# PCIE0_CORE_DBN_CFG_PCIE_CORE register map
Vendor: Texas Instruments
Peripheral module from a debugger description file (folder J7_AHP).
Registers are 32-bit, read-write, reset 0x0 unless marked. A register's access mark holds for its fields unless they carry their own. Offsets are as the file gives them; lines under a group give offsets from that group; [hi:lo] are bit positions; {n}, {i} and the like mark numbered series; 'fields as' and 'values as' point back to an identical list; <NAME> marks a mode.

## PCIE0_CORE_DBN_CFG_PCIE_CORE (part 1 of 6)
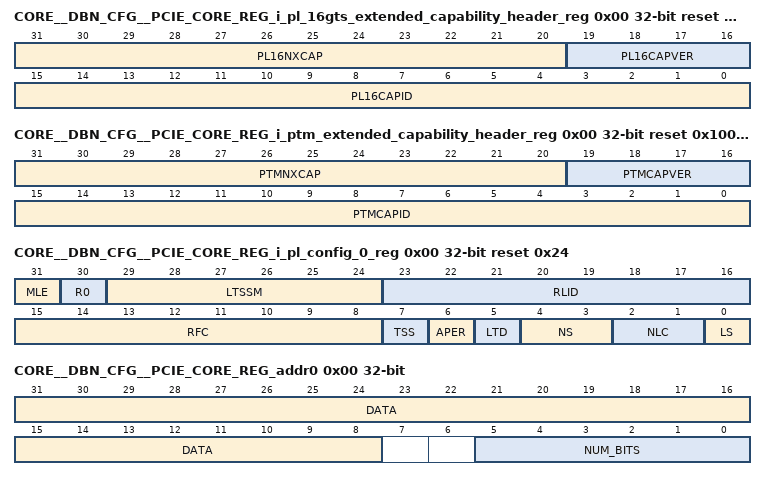
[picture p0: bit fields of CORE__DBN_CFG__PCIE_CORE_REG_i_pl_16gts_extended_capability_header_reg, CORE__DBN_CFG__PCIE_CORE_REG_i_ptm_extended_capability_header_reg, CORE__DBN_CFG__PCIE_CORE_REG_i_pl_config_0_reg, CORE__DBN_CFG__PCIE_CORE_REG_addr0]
0x00 CORE__DBN_CFG__PCIE_CORE_REG_i_pl_16gts_extended_capability_header_reg ro reset 0xA2010026
  [31:20] PL16NXCAP — The offset to the next PCI Extended Capability structure.
  [19:16] PL16CAPVER — This field is a PCI-SIG defined version number that indicates the version of the Capability structure present.
  [15:0] PL16CAPID — Indicates that the associated extended capability structure is for Physical layer 16 GT/s. This field returns a Capability ID of 0026h.
0x00 CORE__DBN_CFG__PCIE_CORE_REG_i_ptm_extended_capability_header_reg ro reset 0x1001F
  [31:20] PTMNXCAP — The offset to the next PCIe Extended Capability structure.
  [19:16] PTMCAPVER — This field is a PCI-SIG defined version number that indicates the version of the Capability structure present.
  [15:0] PTMCAPID — Indicates that the associated extended capability structure is for Precision Time Measurement capability. This field returns a Capability ID of 001Fh.
0x00 CORE__DBN_CFG__PCIE_CORE_REG_i_pl_config_0_reg access per field reset 0x24
  [31] MLE rw — When the Controller is operating as a Root Port, setting this to 1 causes the LTSSM to initiate a loopback and become the loopback master. This bit is not used in the EndPoint Mode.
  [30] R0 ro — A 1 in this field indicates that the remote node advertised Linkwidth Upconfigure Capability in the training sequences in the Configuration.Complete state when the link came up. A 0 indicates that the remote node did not set the Link Upconfigure bit.
  [29:24] LTSSM ro — Current state of the LTSSM. The encoding of the states is given in Appendix C.
  [23:16] RLID ro — Link ID received from other side during link training.
  [15:8] RFC ro — FTS count received from the other side during link training for use at the 2.5 GT/s link speed. The Controller transmits this many FTS sequences while exiting the L0S state, when operating at the 2.5 GT/s speed.
  [7] TSS rw — This bit drives the PIPE_TX_SWING output of the Controller.
  [6] APER rw — This bit controls the reporting of Errors Detected by the PHY. The Errors Detected by the PHY include:- - Received errors indicated on PIPE RxStatus interface, - 8.0 GT/s Invalid Sync Header received error, - 16.0 GT/s Invalid Sync Header received error, If PHY Error Reporting bit is set to 0, the Controller will only report those errors that caused a TLP or DLLP to be dropped because of a Detected PHY Error. If PHY Error Reporting bit is set to 1, the Controller will report all Detected PHY Errors regardless of whether a TLP or DLLP was dropped. The following registers report PHY error in conjunction with this bit: - Correctable Error Status Register, i_corr_err_status, bit-0, Receiver Error Status - Local Error and Status Register, i_local_error_status_register, bit-7, Phy Error In addition to the Errors Detected by the PHY[PCS], the Controller detects the following Physical Layer Protocol Framing Errors: - Framing Errors in the received DLLP and TLP - Ordered Set Block Received Without EDS - Data Block Received After EDS - Illegal Ordered Set Block Received After EDS - Ordered Set Block Received After Skip OS Note: These Errors are always reported independent of the setting of this bit.
  [5] LTD ro — The state of this bit indicates whether the Controller completed link training as an upstream port[EndPoint][=0] or a downstream port[Root Port][=1]. Default value depends on CORE_TYPE strap pin.
  [4:3] NS ro — Current operating speed of link [00 = 2.5G, 01 = 5G, 10 = 8G, 11 = 16G].
  [2:1] NLC ro — Lane count negotiated with other side during link training [00 = x1, 01 = x2, 10 = x4, 11 = x8].
  [0] LS ro — Current state of link [1 = link training complete, 0 = link training not complete].
0x00 CORE__DBN_CFG__PCIE_CORE_REG_addr0 access per field
  [31:8] DATA rw — Bits [31:8] of PCIe Address Register for region N
  [5:0] NUM_BITS rw — Number_bits + 1 bits are passed through from AXI address to the PCIe address
0x00 CORE__DBN_CFG__PCIE_CORE_REG_addr0 access per field
  fields as CORE__DBN_CFG__PCIE_CORE_REG_addr0
0x00 CORE__DBN_CFG__PCIE_CORE_REG_addr0 access per field
  fields as CORE__DBN_CFG__PCIE_CORE_REG_addr0
0x00 CORE__DBN_CFG__PCIE_CORE_REG_addr0 access per field
  fields as CORE__DBN_CFG__PCIE_CORE_REG_addr0
0x00 CORE__DBN_CFG__PCIE_CORE_REG_addr0 access per field
  fields as CORE__DBN_CFG__PCIE_CORE_REG_addr0
0x00 CORE__DBN_CFG__PCIE_CORE_REG_addr0 access per field
  fields as CORE__DBN_CFG__PCIE_CORE_REG_addr0
0x00 CORE__DBN_CFG__PCIE_CORE_REG_addr0 access per field
  fields as CORE__DBN_CFG__PCIE_CORE_REG_addr0
0x00 CORE__DBN_CFG__PCIE_CORE_REG_addr0 access per field
  fields as CORE__DBN_CFG__PCIE_CORE_REG_addr0
0x00 CORE__DBN_CFG__PCIE_CORE_REG_addr0 access per field
  fields as CORE__DBN_CFG__PCIE_CORE_REG_addr0
0x00 CORE__DBN_CFG__PCIE_CORE_REG_addr0 access per field
  fields as CORE__DBN_CFG__PCIE_CORE_REG_addr0
0x00 CORE__DBN_CFG__PCIE_CORE_REG_addr0 access per field
  fields as CORE__DBN_CFG__PCIE_CORE_REG_addr0
0x00 CORE__DBN_CFG__PCIE_CORE_REG_addr0 access per field
  fields as CORE__DBN_CFG__PCIE_CORE_REG_addr0
0x00 CORE__DBN_CFG__PCIE_CORE_REG_addr0 access per field
  fields as CORE__DBN_CFG__PCIE_CORE_REG_addr0
0x00 CORE__DBN_CFG__PCIE_CORE_REG_addr0 access per field
  fields as CORE__DBN_CFG__PCIE_CORE_REG_addr0
0x00 CORE__DBN_CFG__PCIE_CORE_REG_addr0 access per field
  fields as CORE__DBN_CFG__PCIE_CORE_REG_addr0
0x00 CORE__DBN_CFG__PCIE_CORE_REG_addr0 access per field
  fields as CORE__DBN_CFG__PCIE_CORE_REG_addr0
0x00 CORE__DBN_CFG__PCIE_CORE_REG_addr0 access per field
  fields as CORE__DBN_CFG__PCIE_CORE_REG_addr0
0x00 CORE__DBN_CFG__PCIE_CORE_REG_addr0 access per field
  fields as CORE__DBN_CFG__PCIE_CORE_REG_addr0
0x00 CORE__DBN_CFG__PCIE_CORE_REG_addr0 access per field
  fields as CORE__DBN_CFG__PCIE_CORE_REG_addr0
0x00 CORE__DBN_CFG__PCIE_CORE_REG_addr0 access per field
  fields as CORE__DBN_CFG__PCIE_CORE_REG_addr0
0x00 CORE__DBN_CFG__PCIE_CORE_REG_addr0 access per field
  fields as CORE__DBN_CFG__PCIE_CORE_REG_addr0
0x00 CORE__DBN_CFG__PCIE_CORE_REG_addr0 access per field
  fields as CORE__DBN_CFG__PCIE_CORE_REG_addr0
0x00 CORE__DBN_CFG__PCIE_CORE_REG_addr0 access per field
  fields as CORE__DBN_CFG__PCIE_CORE_REG_addr0
0x00 CORE__DBN_CFG__PCIE_CORE_REG_addr0 access per field
  fields as CORE__DBN_CFG__PCIE_CORE_REG_addr0
0x00 CORE__DBN_CFG__PCIE_CORE_REG_addr0 access per field
  fields as CORE__DBN_CFG__PCIE_CORE_REG_addr0
0x00 CORE__DBN_CFG__PCIE_CORE_REG_addr0 access per field
  fields as CORE__DBN_CFG__PCIE_CORE_REG_addr0
0x00 CORE__DBN_CFG__PCIE_CORE_REG_addr0 access per field
  fields as CORE__DBN_CFG__PCIE_CORE_REG_addr0
0x00 CORE__DBN_CFG__PCIE_CORE_REG_addr0 access per field
  fields as CORE__DBN_CFG__PCIE_CORE_REG_addr0
0x00 CORE__DBN_CFG__PCIE_CORE_REG_addr0 access per field
  fields as CORE__DBN_CFG__PCIE_CORE_REG_addr0
0x00 CORE__DBN_CFG__PCIE_CORE_REG_addr0 access per field
  fields as CORE__DBN_CFG__PCIE_CORE_REG_addr0
0x00 CORE__DBN_CFG__PCIE_CORE_REG_addr0 access per field
  fields as CORE__DBN_CFG__PCIE_CORE_REG_addr0
0x00 CORE__DBN_CFG__PCIE_CORE_REG_addr0 access per field
  fields as CORE__DBN_CFG__PCIE_CORE_REG_addr0
0x00 CORE__DBN_CFG__PCIE_CORE_REG_addr0 access per field
  [31:8] DATA rw — Bits [31:8] of AXI Address Register for BAR N
  [5:0] NUM_BITS rw — The value programmed in this register +1 bits are passed through from PCIe to AXI
0x00 CORE__DBN_CFG__PCIE_CORE_REG_addr0 access per field
  [31:8] DATA rw — Bits [31:8] of AXI Address Register for BAR N
  [5:0] NUM_BITS rw — The value programmed in this register +1 bits are passed through from PCIe to AXI
0x00 CORE__DBN_CFG__PCIE_CORE_REG_addr0 access per field
  [31:8] DATA rw — Bits [31:8] of AXI Address Register for BAR N
  [5:0] NUM_BITS rw — The value programmed in this register +1 bits are passed through from PCIe to AXI
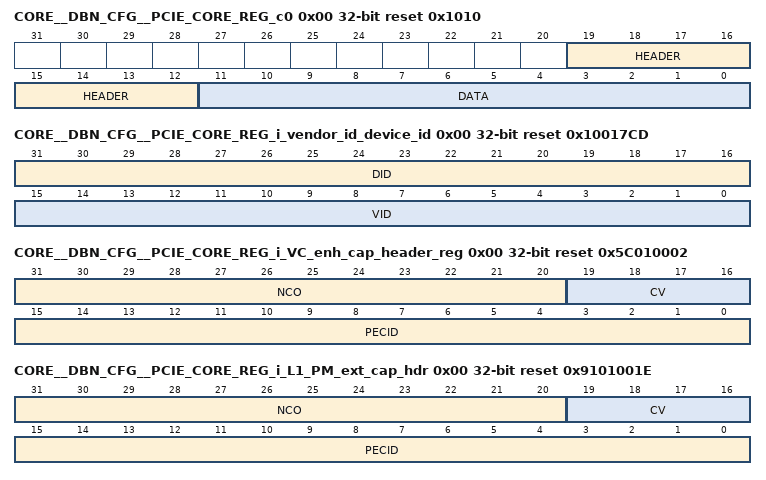
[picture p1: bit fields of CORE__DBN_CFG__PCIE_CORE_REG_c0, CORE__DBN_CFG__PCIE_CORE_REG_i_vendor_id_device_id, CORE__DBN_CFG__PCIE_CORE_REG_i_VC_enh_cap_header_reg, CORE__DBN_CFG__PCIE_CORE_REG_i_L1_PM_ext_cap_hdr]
0x00 CORE__DBN_CFG__PCIE_CORE_REG_c0 reset 0x1010
  [19:12] HEADER — This is the threshold value of the header credits required which is used to flag credit availability in AXI wrapper
  [11:0] DATA — This is the threshold value of the payload credits required which is used to flag credit availability in AXI wrapper
0x00 CORE__DBN_CFG__PCIE_CORE_REG_L0
  [0] CLEAR_LINK_DOWN_BIT_TO_PROCEED — This bit will be set when link down reset comes. client should clear this bit before issueing new traffic to the core
0x00 CORE__DBN_CFG__PCIE_CORE_REG_i_vendor_id_device_id ro reset 0x10017CD
  [31:16] DID — Device ID assigned by the manufacturer of the device. On power-up, the Controller sets it to the value defined in the RTL file reg_defaults.h. This field can be written from the APB bus by setting [21] bit high of the pcie_mgmt_APB_ADDR during a local management register write.
  [15:0] VID — This is the Vendor ID assigned by PCI SIG to the manufacturer of the device. The Vendor ID is set in the Vendor ID Register within the local management register block.
0x00 CORE__DBN_CFG__PCIE_CORE_REG_i_VC_enh_cap_header_reg ro reset 0x5C010002
  [31:20] NCO — Indicates offset to the next PCI Express capability structure. The default next pointer value is dynamic and is dependent on whether the strap or LMI bits are set.
  [19:16] CV — Specifies the SIG assigned value for the version of the capability structure. This field is set by default to 1, but can be modified independently for each PF from the local management bus.
  [15:0] PECID — This field is hardwired to the Capability ID assigned by PCI SIG to the VC Capability.
0x00 CORE__DBN_CFG__PCIE_CORE_REG_i_L1_PM_ext_cap_hdr ro reset 0x9101001E
  [31:20] NCO — Indicates offset to the next PCI Express capability structure. The default next pointer value is dynamic and is dependent on whether the strap or LMI bits are set.
  [19:16] CV — Specifies the SIG assigned value for the version of the capability structure. This field is set by default to 1, but can be modified from the local management bus.
  [15:0] PECID — This field is hardwired to the Capability ID assigned by PCI SIG to the L1 PM Substates Extended Capability Structure [001E hex].
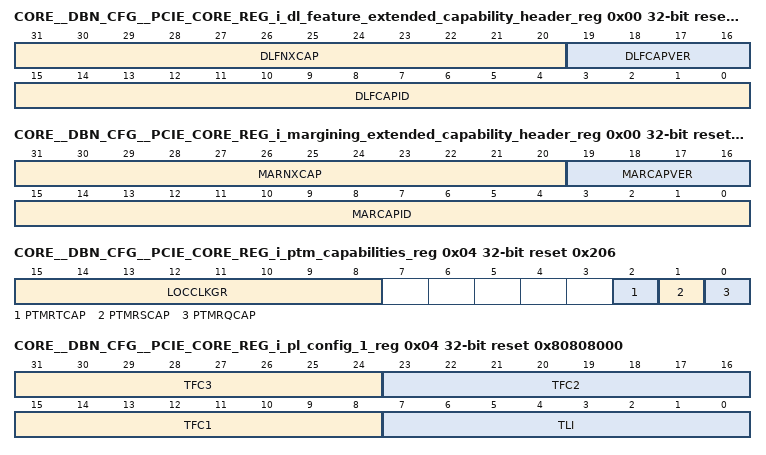
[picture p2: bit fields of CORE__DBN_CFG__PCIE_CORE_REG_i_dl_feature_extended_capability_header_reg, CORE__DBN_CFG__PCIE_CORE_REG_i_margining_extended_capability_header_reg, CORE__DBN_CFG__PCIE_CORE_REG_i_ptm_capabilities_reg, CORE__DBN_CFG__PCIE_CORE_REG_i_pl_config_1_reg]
0x00 CORE__DBN_CFG__PCIE_CORE_REG_i_dl_feature_extended_capability_header_reg ro reset 0x92010025
  [31:20] DLFNXCAP — The offset to the next PCI Extended Capability structure.
  [19:16] DLFCAPVER — This field is a PCI-SIG defined version number that indicates the version of the Capability structure present.
  [15:0] DLFCAPID — Indicates that the associated extended capability structure is the DL Feature Extended Capability. This field returns a Capability ID of 0025h.
0x00 CORE__DBN_CFG__PCIE_CORE_REG_i_margining_extended_capability_header_reg ro reset 0x9C010027
  [31:20] MARNXCAP — The offset to the next PCI Extended Capability structure.
  [19:16] MARCAPVER — This field is a PCI-SIG defined version number that indicates the version of the Capability structure present.
  [15:0] MARCAPID — Indicates that the associated extended capability structure is the Margining Extended Capability. This field returns a Capability ID of 0027h.
0x04 CORE__DBN_CFG__PCIE_CORE_REG_i_pl_16gts_capabilities_reg access not given reset not defined
0x04 CORE__DBN_CFG__PCIE_CORE_REG_i_ptm_capabilities_reg ro reset 0x206
  [15:8] LOCCLKGR — In RC Mode: The Controller uses the CORE_CLK as the Local Clock for PTM. This field is used to indicate the Time Period of the CORE_CLK. If the PTM Root Select is 1, then CORE_CLK is used to provide PTM Master Time. If the PTM Root Select is 0, then CORE_CLK is used to locally track the PTM Master Time received on the PTM_LOCAL_TIMER_IN[63:0] input. By default, this field is set to 8'd2. This bit can be programmed through the local management APB interface if required.
  [2] PTMRTCAP — This bit is used to indicate that the Controller implements PTM Time Source Role and is capable of serving as PTM Root. By default, this bit is set to 1 when the Controller is in RC Mode. This bit can be programmed through the local management APB interface if required. Note: If this bit is programmed to 1, then the PTM Responder Capable bit must also be programmed to 1 by FW.
  [1] PTMRSCAP — This bit is used to indicate support for PTM Responder Role. By default, this bit is set to 1 when the Controller is in RC Mode. This bit can be programmed through the local management APB interface if required. Note: If the PTM Root Capable is programmed to 1, then this bit must also be programmed to 1 by FW.
  [0] PTMRQCAP — This bit is used to indicate support for PTM Requester Role. By default, this bit is set to 0 when the Controller is in RC Mode. This bit can be programmed through the local management APB interface if required.
0x04 CORE__DBN_CFG__PCIE_CORE_REG_i_pl_config_1_reg reset 0x80808000
  [31:24] TFC3 — FTS count transmitted by the Controller in TS1/TS2 sequences during link training. This value must be set based on the time needed by the receiver to acquire sync while exiting from L0S state.
  [23:16] TFC2 — FTS count transmitted by the Controller in TS1/TS2 sequences during link training. This value must be set based on the time needed by the receiver to acquire sync while exiting from L0S state.
  [15:8] TFC1 — FTS count transmitted by the Controller in TS1/TS2 sequences during link training. This value must be set based on the time needed by the receiver to acquire sync while exiting from L0S state.
  [7:0] TLI — Link ID transmitted by the device in training sequences in the Root Port mode.
0x04 CORE__DBN_CFG__PCIE_CORE_REG_addr1
  [31:0] DATA — Bits [63:32] of PCIe Address Register for region N
0x04 CORE__DBN_CFG__PCIE_CORE_REG_addr1
  [31:0] DATA — Bits [63:32] of PCIe Address Register for region N
0x04 CORE__DBN_CFG__PCIE_CORE_REG_addr1
  [31:0] DATA — Bits [63:32] of PCIe Address Register for region N
0x04 CORE__DBN_CFG__PCIE_CORE_REG_addr1
  [31:0] DATA — Bits [63:32] of PCIe Address Register for region N
0x04 CORE__DBN_CFG__PCIE_CORE_REG_addr1
  [31:0] DATA — Bits [63:32] of PCIe Address Register for region N
0x04 CORE__DBN_CFG__PCIE_CORE_REG_addr1
  [31:0] DATA — Bits [63:32] of PCIe Address Register for region N
0x04 CORE__DBN_CFG__PCIE_CORE_REG_addr1
  [31:0] DATA — Bits [63:32] of PCIe Address Register for region N
0x04 CORE__DBN_CFG__PCIE_CORE_REG_addr1
  [31:0] DATA — Bits [63:32] of PCIe Address Register for region N
0x04 CORE__DBN_CFG__PCIE_CORE_REG_addr1
  [31:0] DATA — Bits [63:32] of PCIe Address Register for region N
0x04 CORE__DBN_CFG__PCIE_CORE_REG_addr1
  [31:0] DATA — Bits [63:32] of PCIe Address Register for region N
0x04 CORE__DBN_CFG__PCIE_CORE_REG_addr1
  [31:0] DATA — Bits [63:32] of PCIe Address Register for region N
0x04 CORE__DBN_CFG__PCIE_CORE_REG_addr1
  [31:0] DATA — Bits [63:32] of PCIe Address Register for region N
0x04 CORE__DBN_CFG__PCIE_CORE_REG_addr1
  [31:0] DATA — Bits [63:32] of PCIe Address Register for region N
0x04 CORE__DBN_CFG__PCIE_CORE_REG_addr1
  [31:0] DATA — Bits [63:32] of PCIe Address Register for region N
0x04 CORE__DBN_CFG__PCIE_CORE_REG_addr1
  [31:0] DATA — Bits [63:32] of PCIe Address Register for region N
0x04 CORE__DBN_CFG__PCIE_CORE_REG_addr1
  [31:0] DATA — Bits [63:32] of PCIe Address Register for region N
0x04 CORE__DBN_CFG__PCIE_CORE_REG_addr1
  [31:0] DATA — Bits [63:32] of PCIe Address Register for region N
0x04 CORE__DBN_CFG__PCIE_CORE_REG_addr1
  [31:0] DATA — Bits [63:32] of PCIe Address Register for region N
0x04 CORE__DBN_CFG__PCIE_CORE_REG_addr1
  [31:0] DATA — Bits [63:32] of PCIe Address Register for region N
0x04 CORE__DBN_CFG__PCIE_CORE_REG_addr1
  [31:0] DATA — Bits [63:32] of PCIe Address Register for region N
0x04 CORE__DBN_CFG__PCIE_CORE_REG_addr1
  [31:0] DATA — Bits [63:32] of PCIe Address Register for region N
0x04 CORE__DBN_CFG__PCIE_CORE_REG_addr1
  [31:0] DATA — Bits [63:32] of PCIe Address Register for region N
0x04 CORE__DBN_CFG__PCIE_CORE_REG_addr1
  [31:0] DATA — Bits [63:32] of PCIe Address Register for region N
0x04 CORE__DBN_CFG__PCIE_CORE_REG_addr1
  [31:0] DATA — Bits [63:32] of PCIe Address Register for region N
0x04 CORE__DBN_CFG__PCIE_CORE_REG_addr1
  [31:0] DATA — Bits [63:32] of PCIe Address Register for region N
0x04 CORE__DBN_CFG__PCIE_CORE_REG_addr1
  [31:0] DATA — Bits [63:32] of PCIe Address Register for region N
0x04 CORE__DBN_CFG__PCIE_CORE_REG_addr1
  [31:0] DATA — Bits [63:32] of PCIe Address Register for region N
0x04 CORE__DBN_CFG__PCIE_CORE_REG_addr1
  [31:0] DATA — Bits [63:32] of PCIe Address Register for region N
0x04 CORE__DBN_CFG__PCIE_CORE_REG_addr1
  [31:0] DATA — Bits [63:32] of PCIe Address Register for region N
0x04 CORE__DBN_CFG__PCIE_CORE_REG_addr1
  [31:0] DATA — Bits [63:32] of PCIe Address Register for region N
0x04 CORE__DBN_CFG__PCIE_CORE_REG_addr1
  [31:0] DATA — Bits [63:32] of PCIe Address Register for region N
0x04 CORE__DBN_CFG__PCIE_CORE_REG_addr1
  [31:0] DATA — Bits [63:32] of PCIe Address Register for region N
0x04 CORE__DBN_CFG__PCIE_CORE_REG_addr1
  [31:0] DATA — Bits [63:32] of AXI Address Register for BAR N
0x04 CORE__DBN_CFG__PCIE_CORE_REG_addr1
  [31:0] DATA — Bits [63:32] of AXI Address Register for BAR N
0x04 CORE__DBN_CFG__PCIE_CORE_REG_addr1
  [31:0] DATA — Bits [63:32] of AXI Address Register for BAR N
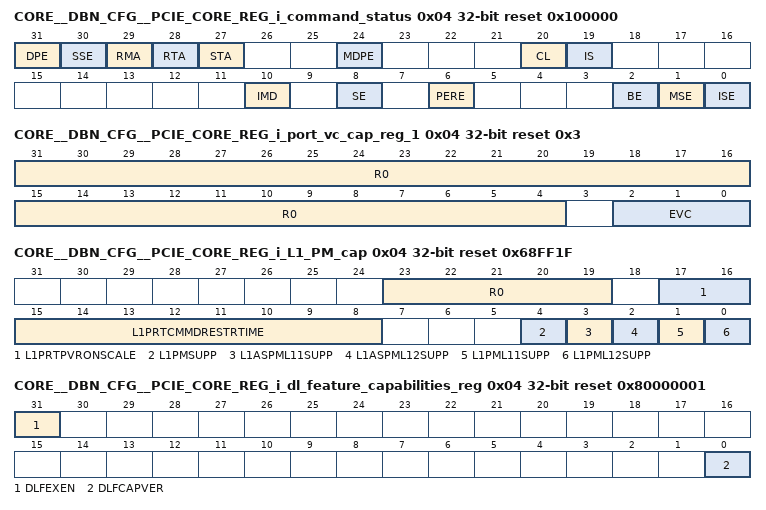
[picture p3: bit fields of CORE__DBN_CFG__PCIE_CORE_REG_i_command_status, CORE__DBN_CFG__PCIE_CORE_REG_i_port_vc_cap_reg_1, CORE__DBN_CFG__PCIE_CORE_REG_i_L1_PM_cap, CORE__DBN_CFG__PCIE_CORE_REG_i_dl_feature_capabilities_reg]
0x04 CORE__DBN_CFG__PCIE_CORE_REG_i_command_status access not given reset 0x100000
  [31] DPE — This bit is set when the Controller has received a poisoned TLP. The Parity Error Response enable bit [bit 6] has no effect on the setting of this bit. This field can also be cleared from the local management bus APB by writing a 1 into this bit position. This field can be forced to 1 from the APB bus by setting [21] bit high of the pcie_mgmt_APB_ADDR during a local management register write. (access R/W1TC)
  [30] SSE — The Controller sets this bit [i]On receiving an error message from the link, if SERR-Enable in PCI Command Register is 1 and SERR-Enable in the Bridge Control Register is also 1. [ii]On any internal Fatal/Non-Fatal error detected, if SERR-Enable in PCI Command Register is 1. This field can also be cleared from the local management APB bus by writing a 1 into this bit position. This field can be forced to 1 from the APB bus by setting [21] bit high of the pcie_mgmt_APB_ADDR during a local management register write. (access R/W1TC)
  [29] RMA — This bit is set when the Controller has received a completion from the link with the Unsupported Request status. This field can also be cleared from the local management APB bus by writing a 1 into this bit position This field can be forced to 1 from the APB bus by setting [21] bit high of the pcie_mgmt_APB_ADDR during a local management register write. (access R/W1TC)
  [28] RTA — This bit is set when the Controller has received a completion from the link with the Completer Abort status. This field can also be cleared from the local management APB bus by writing a 1 into this bit position. This field can be written from the APB bus by setting [21] bit high of the pcie_mgmt_APB_ADDR during a local management register write. (access R/W1TC)
  [27] STA — This bit is set when the Controller has sent a completion to the link with the Completer Abort status. This field can also be cleared from the local management APB bus by writing a 1 into this bit position. This field can be forced to 1 from the APB bus by setting [21] bit high of the pcie_mgmt_APB_ADDR during a local management register write. (access R/W1TC)
  [24] MDPE — When the Parity Error Response enable bit is 1, the Controller sets this bit when it detects the following error conditions: [i] The Controller receives a poisoned request from the link. [ii] The Controller has sent a Poisoned Completion downstream to the link This bit remains 0 when the Parity Error Response enable bit is 0. This field can be forced to 1 from the APB bus by setting [21] bit high of the pcie_mgmt_APB_ADDR during a local management register write. (access R/W1TC)
  [20] CL ro — Indicates the presence of PCI Extended Capabilities registers. This bit is hardwired to 1.
  [19] IS ro — This bit is valid only when the Controller is configured to support legacy interrupts. Indicates that the Controller has a pending interrupt, that is, the Controller has sent an Assert_INTx message but has not transmitted a corresponding Deassert_INTx message.
  [10] IMD rw — Enables or disables the transmission of INTx Assert and De-assert messages from the Controller. The setting of this bit has no effect on the operation of the Controller in the RC mode.
  [8] SE rw — Enables the reporting of fatal and non-fatal errors detected by the Controller to the Root Complex.
  [6] PERE rw — When this bit is 1, the Controller sets the Master Data Parity Error status bit when it detects the following error conditions: [i] The Controller receives a poisoned completion from the link in response to a request. [ii] The Controller sends out a poisoned write request on the link [this may be because an underflow occurred during the packet transfer at the host interface of the Controller.]. When this bit is 0, the Master Data Parity Error status bit is never set.
  [2] BE rw — For a Function with a Type 1 Configurations Space header[Controller in RP Mode], this bit controls forwarding of Memory or I/O Requests by a Port in the Upstream direction. Note: The Controller does not generate any response based on this bit. Client application logic must use this bit and respond to requests appropriately: - When this bit is '1', Client logic can process the Memory and IO Requests received from PCIe Link normally. - When this bit is '0', Client logic must handle Memory and IO Requests received from PCIe Link as Unsupported Requests.
  [1] MSE rw — For a Function with a Type 1 Configuration Space header[Controller in RP Mode], this bit controls the response to Memory Space accesses received on its Primary Side. Note: The Controller does not generate any response based on this bit. - Client must check for this bit to be '1' before initiating any Memory requests on the pcie_master_AXI interface.
  [0] ISE rw — For a Function with a Type 1 Configuration Space header [Controller in RP Mode] , this bit controls the response to I/O Space accesses received on its Primary Side. Note: The Controller does not generate any response based on this bit. - Client must check for this bit to be '1' before initiating any IO requests on the pcie_master_AXI interface.
0x04 CORE__DBN_CFG__PCIE_CORE_REG_i_port_vc_cap_reg_1 ro reset 0x3
  [31:4] R0, [2:0] EVC
0x04 CORE__DBN_CFG__PCIE_CORE_REG_i_L1_PM_cap ro reset 0x68FF1F
  [23:19] R0 — Along with the Port T_POWER_ON Scale field in the L1 PM Substates Capabilities register sets the time [in us] that this Port requires the port on the opposite side of Link to wait in L1.2.Exit after sampling CLKREQ# asserted before actively driving the interface. The value of Port T_POWER_ON is calculated by multiplying the value in this field by the scale value in the Port T_POWER_ON Scale field in the L1 PM Substates Capabilities register. T Power On is the minimum amount of time that each component must wait in L1.2.Exit after sampling CLKREQ# asserted before actively driving the interface. This is to ensure no device is ever actively driving into an unpowered component.
  [17:16] L1PRTPVRONSCALE — Specifies the scale used for the Port T_POWER_ON Value field in the L1 PM Substates Capabilities register. Range of Values 00b = 2us 01b = 10us 10b = 100us 11b = Reserved Default value is 00.
  [15:8] L1PRTCMMDRESTRTIME — Time [in us] required for this Port to re-establish common mode during exit from PM or ASPM L1.2 substate
  [4] L1PMSUPP — When Set this bit indicates that this Port supports L1 PM Substates.
  [3] L1ASPML11SUPP — When Set this bit indicates that ASPM L1.1 is supported.
  [2] L1ASPML12SUPP — When Set this bit indicates that ASPM L1.2 is supported.
  [1] L1PML11SUPP — When Set this bit indicates that PCI-PM L1.1 is supported.
  [0] L1PML12SUPP — When Set this bit indicates that PCI-PM L1.2 is supported.
0x04 CORE__DBN_CFG__PCIE_CORE_REG_i_dl_feature_capabilities_reg ro reset 0x80000001
  [31] DLFEXEN — If Set, this bit indicates that this Port will enter the DL_Feature negotiation state prior to Link Initialization.
  [0] DLFCAPVER — This bit indicates that this Port supports the Scaled Flow Control Feature.
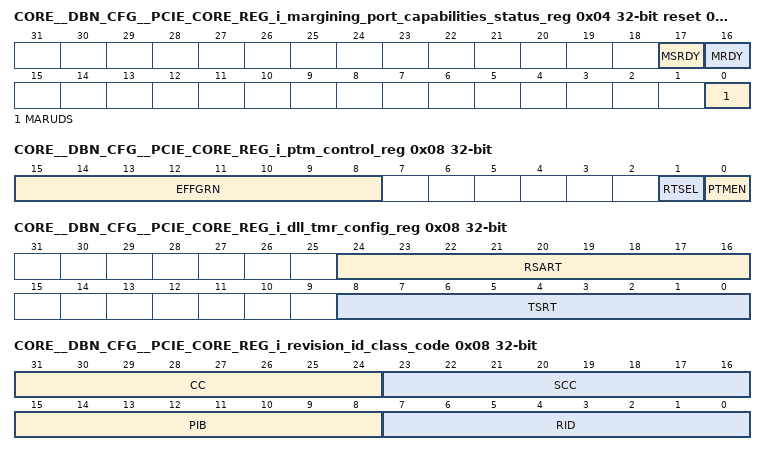
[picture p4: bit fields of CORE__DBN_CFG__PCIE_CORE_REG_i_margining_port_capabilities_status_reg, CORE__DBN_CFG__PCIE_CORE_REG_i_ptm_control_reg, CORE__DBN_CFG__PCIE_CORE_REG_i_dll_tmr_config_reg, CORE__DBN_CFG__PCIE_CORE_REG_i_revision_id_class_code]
0x04 CORE__DBN_CFG__PCIE_CORE_REG_i_margining_port_capabilities_status_reg ro reset 0x1
  [17] MSRDY — When Margining uses Driver Software is Set, then this bit, when Set, indicates that the required software has performed the required initialization. The value of this bit is Undefined if Margining users Driver Software is Clear. The Controller implementation sets the default value of this bit to 0. The driver software must initialize the Rx Margining parameters in the Local Management Lane Margining Registers and then program this bit to 1.
  [16] MRDY — Indicates when the Margining feature is ready to accept margining commands. If the Margining uses Driver Software bit is 1, then the Controller sets this status bit when the Margining Software Ready bit is set and the Link is in Gen4 L0 state. If the Margining uses Driver Software bit is 0, then the Controller sets this status bit when the Link is in Gen4 L0 state.
  [0] MARUDS — If Set, indicates that Margining is partially implemented using Device Driver software. Margining Software Ready indicates when this software is initialized. If Clear, Margining does not require device driver software. The Controller implementation requires driver software to initialize the Rx Margining parameter values in Local Management Registers for Lane Margining. Hence, the default value of this bit is set to 1.
0x08 CORE__DBN_CFG__PCIE_CORE_REG_i_pl_16gts_control_reg access not given reset not defined
0x08 CORE__DBN_CFG__PCIE_CORE_REG_i_ptm_control_reg access per field
  [15:8] EFFGRN ro — This field is used only in PTM Requester Mode and is not used in RC Mode. This field is set to 00 by default in RC Mode.
  [1] RTSEL rw — This field is configured by System SW. When set to 1 and when PTM Enable bit is aslo set to 1, this PTM Source is the PTM Root. Default value of this bit is 0.
  [0] PTMEN rw — When Set, this function is permitted to participate in the PTM mechanism as PTM Requester. By default, this bit is set to 0.
0x08 CORE__DBN_CFG__PCIE_CORE_REG_i_dll_tmr_config_reg
  [24:16] RSART — Additional receive side ACK-NAK timer timeout interval. This 9-bit value is added as a signed 2's complement number to the internal ACK-NAK timer timeout value computed by the Controller based on the PCI Express Specifications. This enables the user to make minor adjustments to the spec-defined replay timer settings.Its value is in multiples of [2 Symbol Times] At Gen1 adjustment range = [+2040 ns to -2048 ns]. At Gen2 adjustment range = [+1020 ns to -1024 ns]. At Gen3 adjustment range = [+510 ns to -512 ns].
  [8:0] TSRT — Additional transmit-side replay timer timeout interval. This 9-bit value is added as a signed 2's complement number to the internal replay timer timeout value computed by the Controller based on the PCI Express Specifications. This enables the user to make minor adjustments to the spec-defined replay timer settings. Its value is in multiples of [2 Symbol Times] At Gen1 adjustment range = [+2040 ns to -2048 ns]. At Gen2 adjustment range = [+1020 ns to -1024 ns]. At Gen3 adjustment range = [+510 ns to -512 ns].
0x08 CORE__DBN_CFG__PCIE_CORE_REG_desc0
  [31:0] DATA — Lowest 32-bits of PCIe Descriptor Register for region N
0x08 CORE__DBN_CFG__PCIE_CORE_REG_desc0
  fields as CORE__DBN_CFG__PCIE_CORE_REG_desc0
0x08 CORE__DBN_CFG__PCIE_CORE_REG_desc0
  fields as CORE__DBN_CFG__PCIE_CORE_REG_desc0
0x08 CORE__DBN_CFG__PCIE_CORE_REG_desc0
  fields as CORE__DBN_CFG__PCIE_CORE_REG_desc0
0x08 CORE__DBN_CFG__PCIE_CORE_REG_desc0
  fields as CORE__DBN_CFG__PCIE_CORE_REG_desc0
0x08 CORE__DBN_CFG__PCIE_CORE_REG_desc0
  fields as CORE__DBN_CFG__PCIE_CORE_REG_desc0
0x08 CORE__DBN_CFG__PCIE_CORE_REG_desc0
  fields as CORE__DBN_CFG__PCIE_CORE_REG_desc0
0x08 CORE__DBN_CFG__PCIE_CORE_REG_desc0
  fields as CORE__DBN_CFG__PCIE_CORE_REG_desc0
0x08 CORE__DBN_CFG__PCIE_CORE_REG_desc0
  fields as CORE__DBN_CFG__PCIE_CORE_REG_desc0
0x08 CORE__DBN_CFG__PCIE_CORE_REG_desc0
  fields as CORE__DBN_CFG__PCIE_CORE_REG_desc0
0x08 CORE__DBN_CFG__PCIE_CORE_REG_desc0
  fields as CORE__DBN_CFG__PCIE_CORE_REG_desc0
0x08 CORE__DBN_CFG__PCIE_CORE_REG_desc0
  fields as CORE__DBN_CFG__PCIE_CORE_REG_desc0
0x08 CORE__DBN_CFG__PCIE_CORE_REG_desc0
  fields as CORE__DBN_CFG__PCIE_CORE_REG_desc0
0x08 CORE__DBN_CFG__PCIE_CORE_REG_desc0
  fields as CORE__DBN_CFG__PCIE_CORE_REG_desc0
0x08 CORE__DBN_CFG__PCIE_CORE_REG_desc0
  fields as CORE__DBN_CFG__PCIE_CORE_REG_desc0
0x08 CORE__DBN_CFG__PCIE_CORE_REG_desc0
  fields as CORE__DBN_CFG__PCIE_CORE_REG_desc0
0x08 CORE__DBN_CFG__PCIE_CORE_REG_desc0
  fields as CORE__DBN_CFG__PCIE_CORE_REG_desc0
0x08 CORE__DBN_CFG__PCIE_CORE_REG_desc0
  fields as CORE__DBN_CFG__PCIE_CORE_REG_desc0
0x08 CORE__DBN_CFG__PCIE_CORE_REG_desc0
  fields as CORE__DBN_CFG__PCIE_CORE_REG_desc0
0x08 CORE__DBN_CFG__PCIE_CORE_REG_desc0
  fields as CORE__DBN_CFG__PCIE_CORE_REG_desc0
0x08 CORE__DBN_CFG__PCIE_CORE_REG_desc0
  fields as CORE__DBN_CFG__PCIE_CORE_REG_desc0
0x08 CORE__DBN_CFG__PCIE_CORE_REG_desc0
  fields as CORE__DBN_CFG__PCIE_CORE_REG_desc0
0x08 CORE__DBN_CFG__PCIE_CORE_REG_desc0
  fields as CORE__DBN_CFG__PCIE_CORE_REG_desc0
0x08 CORE__DBN_CFG__PCIE_CORE_REG_desc0
  fields as CORE__DBN_CFG__PCIE_CORE_REG_desc0
0x08 CORE__DBN_CFG__PCIE_CORE_REG_desc0
  fields as CORE__DBN_CFG__PCIE_CORE_REG_desc0
0x08 CORE__DBN_CFG__PCIE_CORE_REG_desc0
  fields as CORE__DBN_CFG__PCIE_CORE_REG_desc0
0x08 CORE__DBN_CFG__PCIE_CORE_REG_desc0
  fields as CORE__DBN_CFG__PCIE_CORE_REG_desc0
0x08 CORE__DBN_CFG__PCIE_CORE_REG_desc0
  fields as CORE__DBN_CFG__PCIE_CORE_REG_desc0
0x08 CORE__DBN_CFG__PCIE_CORE_REG_desc0
  fields as CORE__DBN_CFG__PCIE_CORE_REG_desc0
0x08 CORE__DBN_CFG__PCIE_CORE_REG_desc0
  fields as CORE__DBN_CFG__PCIE_CORE_REG_desc0
0x08 CORE__DBN_CFG__PCIE_CORE_REG_desc0
  fields as CORE__DBN_CFG__PCIE_CORE_REG_desc0
0x08 CORE__DBN_CFG__PCIE_CORE_REG_desc0
  fields as CORE__DBN_CFG__PCIE_CORE_REG_desc0
0x08 CORE__DBN_CFG__PCIE_CORE_REG_i_revision_id_class_code ro
  [31:24] CC — Identifies the function of the device. On power-up, the Controller sets it to the value defined in the RTL file reg_defaults.h. This field can be written from the APB bus by setting [21] bit high of the pcie_mgmt_APB_ADDR during a local management register write.
  [23:16] SCC — Identifies a sub-category within the selected function. This field can be written from the APB bus by setting [21] bit high of the pcie_mgmt_APB_ADDR during a local management register write.
  [15:8] PIB — Identifies the register set layout of the device. This field can be written from the APB bus by setting [21] bit high of the pcie_mgmt_APB_ADDR during a local management register write.
  [7:0] RID — Assigned by the manufacturer of the device to identify the revision number of the device. This field can be written from the APB bus by setting [21] bit high of the pcie_mgmt_APB_ADDR during a local management register write.
0x08 CORE__DBN_CFG__PCIE_CORE_REG_i_port_vc_cap_reg_2 ro
  [31:0] R1
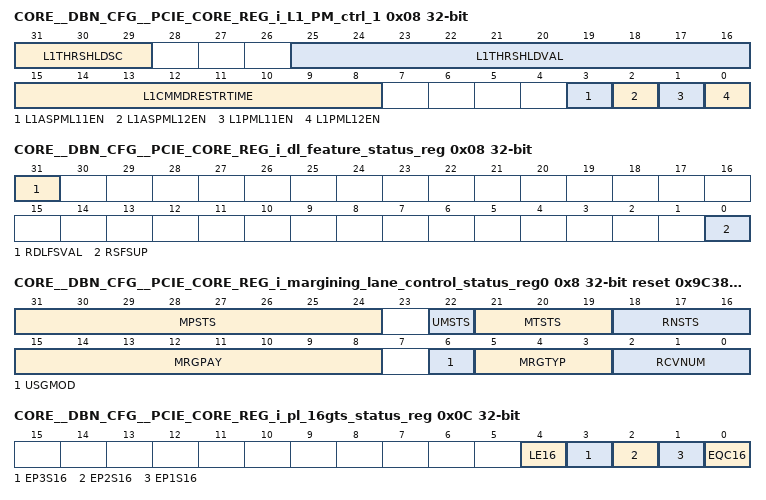
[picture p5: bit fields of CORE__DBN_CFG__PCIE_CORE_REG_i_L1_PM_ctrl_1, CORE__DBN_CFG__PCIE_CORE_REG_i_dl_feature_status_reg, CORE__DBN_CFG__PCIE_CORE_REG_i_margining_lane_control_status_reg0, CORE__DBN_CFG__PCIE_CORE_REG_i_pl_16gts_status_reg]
0x08 CORE__DBN_CFG__PCIE_CORE_REG_i_L1_PM_ctrl_1
  [31:29] L1THRSHLDSC — This field provides a scale for the value contained within the LTR_L1.2_THRESHOLD_Value. 000 - Value times 1 ns 001 - Value times 32 ns 010 - Value times 1024 ns 011 - Value times 32,768 ns 100 - Value times 1,048,576 ns 101 - Value times 33,554,422ns 110-111 - Not permitted
  [25:16] L1THRSHLDVAL — Along with the LTR_L1.2_THRESHOLD_Scale, this field indicates the LTR threshold used to determine if entry into L1 results in L1.1 [if enabled] or L1.2 [if enabled].
  [15:8] L1CMMDRESTRTIME — Sets value of TCOMMONMODE [in us], which must be used by the Downstream Port for timing the re-establishment of common mode. This field must only be modified when the ASPM L1.2 Enable and PCI-PM L1.2 Enable bits are both Clear. This field is reserved since both PCI-PM L1.2 and ASPM L1.2 are Not Supported in this configuration of the Controller.
  [3] L1ASPML11EN — When Set this bit enables ASPM L1.1.
  [2] L1ASPML12EN — When Set this bit enables ASPM L1.2.
  [1] L1PML11EN — When Set this bit enables PCI-PM L1.1.
  [0] L1PML12EN — When Set this bit enables PCI-PM L1.2.
0x08 CORE__DBN_CFG__PCIE_CORE_REG_i_dl_feature_status_reg ro
  [31] RDLFSVAL — This bit indicates that the Port has received a Data Link Feature DLLP in state DL_Feature [see Section 3.2.1] and that the Remote Data Link Feature Supported and Remote Data Link Feature Ack fields are meaningful. This bit is Cleared on entry to state DL_Inactive. Default is 0b.
  [0] RSFSUP — This bit indicates that the Remote end Device supports the Scaled Flow Control Feature.
{0x8+4i} CORE__DBN_CFG__PCIE_CORE_REG_i_margining_lane_control_status_reg{i} access per field reset 0x9C38 (i=0..3)
  [31:24] MPSTS ro — Margin Payload Status for Margining Commands. This field is reset upon DL Down.
  [22] UMSTS ro — Usage Model Status for Margining Commands. This field is reset upon DL Down.
  [21:19] MTSTS ro — Margin Type Status for Margining Commands. This field is reset upon DL Down.
  [18:16] RNSTS ro — Receiver Number Status for Margining Commands. This field is reset upon DL Down.
  [15:8] MRGPAY rw — Margin Payload for Margining Commands. This field is reset upon DL Down.
  [6] USGMOD rw — Usage Model for Margining Commands. This field is reset upon DL Down.
  [5:3] MRGTYP rw — Margin Type for Margining Commands. This field is reset upon DL Down.
  [2:0] RCVNUM rw — Receiver Number for Margining Commands. This field is reset upon DL Down.
0x0C CORE__DBN_CFG__PCIE_CORE_REG_i_pl_16gts_status_reg access not given
  [4] LE16 — When the Controller [RP] receives an 16GTs equalization request from an Upstream Port the Controller internally sets this bit to 1. [i.e. when RP is in the Recovery.RcvrCfg state and receives 8 consecutive TS2 Ordered Sets with the Request Equalization bit set to 1b] The LOCAL_INTERRUPT output is also asserted if Link Equalization Request Interrupt Enable is enabled. (access R/W1TC)
  [3] EP3S16 ro — This bit, when set to 1, indicates that the Phase 3 of the Transmitter Equalization procedure has completed successfully for 16.0 GT/s. STICKY.
  [2] EP2S16 ro — This bit, when set to 1, indicates that the Phase 2 of the Transmitter Equalization procedure has completed successfully for 16.0 GT/s. STICKY.
  [1] EP1S16 ro — This bit, when set to 1, indicates that the Phase 1 of the Transmitter Equalization procedure has completed successfully for 16.0 GT/s. STICKY.
  [0] EQC16 ro — This bit, when set to 1, indicates that the Transmitter Equalization procedure has completed for 16.0 GT/s. STICKY.
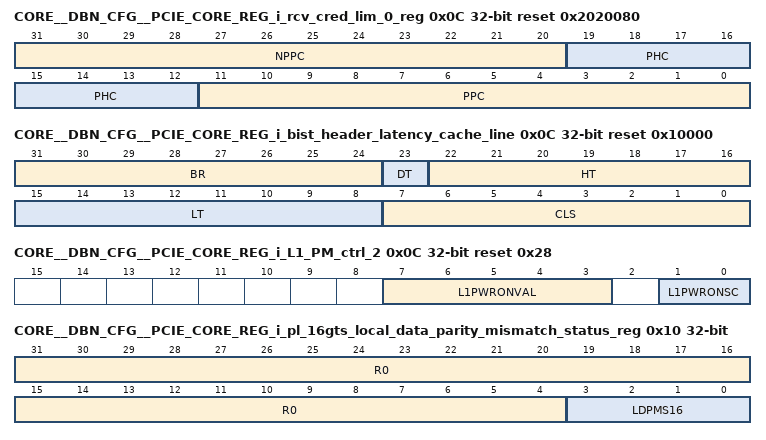
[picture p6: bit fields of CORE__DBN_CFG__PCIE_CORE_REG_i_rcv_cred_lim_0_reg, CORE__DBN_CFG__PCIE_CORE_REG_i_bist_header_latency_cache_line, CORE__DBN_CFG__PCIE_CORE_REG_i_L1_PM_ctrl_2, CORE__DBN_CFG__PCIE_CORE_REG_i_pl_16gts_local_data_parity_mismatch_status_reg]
0x0C CORE__DBN_CFG__PCIE_CORE_REG_i_rcv_cred_lim_0_reg reset 0x2020080
  [31:20] NPPC — Non-Posted payload credit limit advertised by the Controller for VC 0 . This field is in units of 4 DWords, 16 DWords or 64 DWords based on the Local Posted Payload Credit Scale for VC 0. 00b => [units of 4 DWords] 01b => [units of 4 DWords] 10b => [units of 16 DWords] 11b => [units of 64 DWords] Note: When Scaled FLow Control is Activated, the programmed credit value is advertised in the InitFC DLLPs. Else, the programmed credit value is internally normalized to units of 4 DW and then advertised in the InitFC DLLPs. Caution: The programmed Header and Payload credit values must not exceed the actual size of the Receive Buffer.
  [19:12] PHC — Posted header credit limit advertised by the Controller for VC 0. This field is in units of 1, 4 or 16 Packet Headers based on the Local Posted Header Credit Scale for VC 0. 00b => [units of 1 Packet Header] 01b => [units of 1 Packet Header] 10b => [units of 4 Packet Headers] 11b => [units of 16 Packet Headers] Note: When Scaled FLow Control is Activated, the programmed credit value is advertised in the InitFC DLLPs. Else, the programmed credit value is internally normalized to units of [1 Packet Header] and then advertised in the InitFC DLLPs. Note: Packet Header represents one maximum-size TLP Header + TLP Digest + maximum number of EndEnd TLP Prefixes permitted in a TLP. Caution: The programmed Header and Payload credit values must not exceed the actual size of the Receive Buffer.
  [11:0] PPC — Posted payload credit limit advertised by the Controller for VC 0. This field is in units of 4 DWords, 16 DWords or 64 DWords based on the Local Posted Payload Credit Scale for VC 0. 00b => [units of 4 DWords] 01b => [units of 4 DWords] 10b => [units of 16 DWords] 11b => [units of 64 DWords] Note: When Scaled FLow Control is Activated, the programmed credit value is advertised in the InitFC DLLPs. Else, the programmed credit value is internally normalized to units of 4 DW and then advertised in the InitFC DLLPs. Caution: The programmed Header and Payload credit values must not exceed the actual size of the Receive Buffer.
0x0C CORE__DBN_CFG__PCIE_CORE_REG_desc1
  [31:0] DATA — Lower middle 32-bits of PCIe Descriptor Register for region N
0x0C CORE__DBN_CFG__PCIE_CORE_REG_desc1
  fields as CORE__DBN_CFG__PCIE_CORE_REG_desc1
0x0C CORE__DBN_CFG__PCIE_CORE_REG_desc1
  fields as CORE__DBN_CFG__PCIE_CORE_REG_desc1
0x0C CORE__DBN_CFG__PCIE_CORE_REG_desc1
  fields as CORE__DBN_CFG__PCIE_CORE_REG_desc1
0x0C CORE__DBN_CFG__PCIE_CORE_REG_desc1
  fields as CORE__DBN_CFG__PCIE_CORE_REG_desc1
0x0C CORE__DBN_CFG__PCIE_CORE_REG_desc1
  fields as CORE__DBN_CFG__PCIE_CORE_REG_desc1
0x0C CORE__DBN_CFG__PCIE_CORE_REG_desc1
  fields as CORE__DBN_CFG__PCIE_CORE_REG_desc1
0x0C CORE__DBN_CFG__PCIE_CORE_REG_desc1
  fields as CORE__DBN_CFG__PCIE_CORE_REG_desc1
0x0C CORE__DBN_CFG__PCIE_CORE_REG_desc1
  fields as CORE__DBN_CFG__PCIE_CORE_REG_desc1
0x0C CORE__DBN_CFG__PCIE_CORE_REG_desc1
  fields as CORE__DBN_CFG__PCIE_CORE_REG_desc1
0x0C CORE__DBN_CFG__PCIE_CORE_REG_desc1
  fields as CORE__DBN_CFG__PCIE_CORE_REG_desc1
0x0C CORE__DBN_CFG__PCIE_CORE_REG_desc1
  fields as CORE__DBN_CFG__PCIE_CORE_REG_desc1
0x0C CORE__DBN_CFG__PCIE_CORE_REG_desc1
  fields as CORE__DBN_CFG__PCIE_CORE_REG_desc1
0x0C CORE__DBN_CFG__PCIE_CORE_REG_desc1
  fields as CORE__DBN_CFG__PCIE_CORE_REG_desc1
0x0C CORE__DBN_CFG__PCIE_CORE_REG_desc1
  fields as CORE__DBN_CFG__PCIE_CORE_REG_desc1
0x0C CORE__DBN_CFG__PCIE_CORE_REG_desc1
  fields as CORE__DBN_CFG__PCIE_CORE_REG_desc1
0x0C CORE__DBN_CFG__PCIE_CORE_REG_desc1
  fields as CORE__DBN_CFG__PCIE_CORE_REG_desc1
0x0C CORE__DBN_CFG__PCIE_CORE_REG_desc1
  fields as CORE__DBN_CFG__PCIE_CORE_REG_desc1
0x0C CORE__DBN_CFG__PCIE_CORE_REG_desc1
  fields as CORE__DBN_CFG__PCIE_CORE_REG_desc1
0x0C CORE__DBN_CFG__PCIE_CORE_REG_desc1
  fields as CORE__DBN_CFG__PCIE_CORE_REG_desc1
0x0C CORE__DBN_CFG__PCIE_CORE_REG_desc1
  fields as CORE__DBN_CFG__PCIE_CORE_REG_desc1
0x0C CORE__DBN_CFG__PCIE_CORE_REG_desc1
  fields as CORE__DBN_CFG__PCIE_CORE_REG_desc1
0x0C CORE__DBN_CFG__PCIE_CORE_REG_desc1
  fields as CORE__DBN_CFG__PCIE_CORE_REG_desc1
0x0C CORE__DBN_CFG__PCIE_CORE_REG_desc1
  fields as CORE__DBN_CFG__PCIE_CORE_REG_desc1
0x0C CORE__DBN_CFG__PCIE_CORE_REG_desc1
  fields as CORE__DBN_CFG__PCIE_CORE_REG_desc1
0x0C CORE__DBN_CFG__PCIE_CORE_REG_desc1
  fields as CORE__DBN_CFG__PCIE_CORE_REG_desc1
0x0C CORE__DBN_CFG__PCIE_CORE_REG_desc1
  fields as CORE__DBN_CFG__PCIE_CORE_REG_desc1
0x0C CORE__DBN_CFG__PCIE_CORE_REG_desc1
  fields as CORE__DBN_CFG__PCIE_CORE_REG_desc1
0x0C CORE__DBN_CFG__PCIE_CORE_REG_desc1
  fields as CORE__DBN_CFG__PCIE_CORE_REG_desc1
0x0C CORE__DBN_CFG__PCIE_CORE_REG_desc1
  fields as CORE__DBN_CFG__PCIE_CORE_REG_desc1
0x0C CORE__DBN_CFG__PCIE_CORE_REG_desc1
  fields as CORE__DBN_CFG__PCIE_CORE_REG_desc1
0x0C CORE__DBN_CFG__PCIE_CORE_REG_desc1
  fields as CORE__DBN_CFG__PCIE_CORE_REG_desc1
0x0C CORE__DBN_CFG__PCIE_CORE_REG_i_bist_header_latency_cache_line access per field reset 0x10000
  [31:24] BR ro — BIST control register. This field can be written from the APB bus by setting [21] bit high of the pcie_mgmt_APB_ADDR during a local management register write.
  [23] DT ro — Identifies whether the device supports a single Function or multiple Functions. Hardwired to zero
  [22:16] HT ro — Identifies format of header. This field is hardwired to 1.
  [15:8] LT ro — This is an unused field and is hardwired to 0.
  [7:0] CLS rw — Cache Line Size Register defined in PCI Specifications 3.0. This field can be read or written, both from the link and from the local management bus, but its value is not used.
0x0C CORE__DBN_CFG__PCIE_CORE_REG_i_port_vc_ctrl_sts_reg ro
  [31:0] R2
0x0C CORE__DBN_CFG__PCIE_CORE_REG_i_L1_PM_ctrl_2 reset 0x28
  [7:3] L1PWRONVAL — Along with the T_POWER_ON Scale sets the minimum amount of time [in us] that the Port must wait in L1.2.Exit after sampling CLKREQ# asserted before actively driving the interface. T_POWER_ON is calculated by multiplying the value in this field by the value in the T_POWER_ON Scale field.
  [1:0] L1PWRONSC — Specifies the scale used for T_POWER_ON Value. Range of Values 00b = 2us 01b = 10us 10b = 100us 11b = Reserved
0x10 CORE__DBN_CFG__PCIE_CORE_REG_i_pl_16gts_local_data_parity_mismatch_status_reg access not given
  [31:4] R0 ro
  [3:0] LDPMS16 — Each bit indicates if the corresponding Lane detected a Data Parity mismatch. A value of 1b indicates that a mismatch was detected on the corresponding Lane Number. (access R/W1TC)
